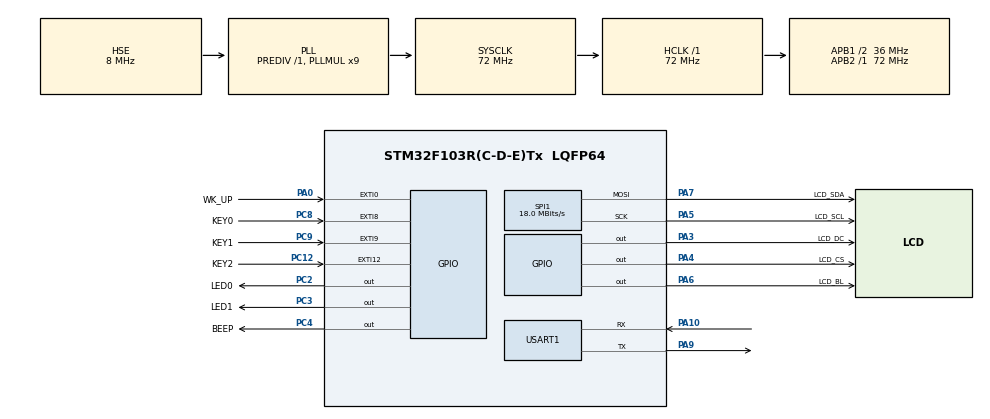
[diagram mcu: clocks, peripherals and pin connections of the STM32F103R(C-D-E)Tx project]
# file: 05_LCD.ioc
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Mcu.Family=STM32F1
Mcu.Name=STM32F103R(C-D-E)Tx
Mcu.Package=LQFP64
NVIC.EXTI0_IRQn=true\:2\:0\:true\:false\:true\:true\:true\:true
NVIC.EXTI15_10_IRQn=true\:2\:2\:true\:false\:true\:true\:true\:true
NVIC.EXTI9_5_IRQn=true\:2\:1\:true\:false\:true\:true\:true\:true
NVIC.PriorityGroup=NVIC_PRIORITYGROUP_2
NVIC.USART1_IRQn=true\:1\:0\:true\:false\:true\:true\:true\:true
PA0-WKUP.GPIO_Label=WK_UP
PA0-WKUP.GPIO_ModeDefaultEXTI=GPIO_MODE_IT_RISING
PA0-WKUP.GPIO_PuPd=GPIO_PULLDOWN
PA0-WKUP.Signal=GPXTI0
PA10.Mode=Asynchronous
PA10.Signal=USART1_RX
PA13.Mode=Serial_Wire
PA13.Signal=SYS_JTMS-SWDIO
PA14.Mode=Serial_Wire
PA14.Signal=SYS_JTCK-SWCLK
PA3.GPIO_Label=LCD_DC
PA3.GPIO_Speed=GPIO_SPEED_FREQ_HIGH
PA3.PinState=GPIO_PIN_SET
PA3.Signal=GPIO_Output
PA4.GPIO_Label=LCD_CS
PA4.GPIO_Speed=GPIO_SPEED_FREQ_HIGH
PA4.PinState=GPIO_PIN_SET
PA4.Signal=GPIO_Output
PA5.GPIO_Label=LCD_SCL
PA5.Mode=TX_Only_Simplex_Unidirect_Master
PA5.Signal=SPI1_SCK
PA6.GPIO_Label=LCD_BL
PA6.PinState=GPIO_PIN_RESET
PA6.Signal=GPIO_Output
PA7.GPIO_Label=LCD_SDA
PA7.Mode=TX_Only_Simplex_Unidirect_Master
PA7.Signal=SPI1_MOSI
PA9.Mode=Asynchronous
PA9.Signal=USART1_TX
PC12.GPIO_Label=KEY2
PC12.GPIO_ModeDefaultEXTI=GPIO_MODE_IT_FALLING
PC12.GPIO_PuPd=GPIO_PULLUP
PC12.Signal=GPXTI12
PC14-OSC32_IN.Mode=LSE-External-Oscillator
PC14-OSC32_IN.Signal=RCC_OSC32_IN
PC15-OSC32_OUT.Mode=LSE-External-Oscillator
PC15-OSC32_OUT.Signal=RCC_OSC32_OUT
PC2.GPIO_Label=LED0
PC2.Signal=GPIO_Output
PC3.GPIO_Label=LED1
PC3.Signal=GPIO_Output
PC4.GPIO_Label=BEEP
PC4.Signal=GPIO_Output
PC8.GPIO_Label=KEY0
PC8.GPIO_ModeDefaultEXTI=GPIO_MODE_IT_FALLING
PC8.GPIO_PuPd=GPIO_PULLUP
PC8.Signal=GPXTI8
PC9.GPIO_Label=KEY1
PC9.GPIO_ModeDefaultEXTI=GPIO_MODE_IT_FALLING
PC9.GPIO_PuPd=GPIO_PULLUP
PC9.Signal=GPXTI9
PD0-OSC_IN.Mode=HSE-External-Oscillator
PD0-OSC_IN.Signal=RCC_OSC_IN
PD1-OSC_OUT.Mode=HSE-External-Oscillator
PD1-OSC_OUT.Signal=RCC_OSC_OUT
ProjectManager.HeapSize=0x200
ProjectManager.StackSize=0x400
ProjectManager.TargetToolchain=STM32CubeIDE
RCC.AHBFreq_Value=72000000
RCC.APB1CLKDivider=RCC_HCLK_DIV2
RCC.APB1Freq_Value=36000000
RCC.APB1TimFreq_Value=72000000
RCC.APB2Freq_Value=72000000
RCC.APB2TimFreq_Value=72000000
RCC.HCLKFreq_Value=72000000
RCC.PLLMUL=RCC_PLL_MUL9
RCC.PLLSourceVirtual=RCC_PLLSOURCE_HSE
RCC.SYSCLKFreq_VALUE=72000000
RCC.SYSCLKSource=RCC_SYSCLKSOURCE_PLLCLK
RCC.USBFreq_Value=72000000
SPI1.BaudRatePrescaler=SPI_BAUDRATEPRESCALER_4
SPI1.CalculateBaudRate=18.0 MBits/s
SPI1.Direction=SPI_DIRECTION_2LINES
SPI1.Mode=SPI_MODE_MASTER
SPI1.VirtualType=VM_MASTER
USART1.VirtualMode=VM_ASYNC
board=custom

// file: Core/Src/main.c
/* USER CODE BEGIN Header */
/**
  ******************************************************************************
  * @file           : main.c
  * @brief          : Main program body
  ******************************************************************************
  * @attention
  *
  * Copyright (c) 2025 STMicroelectronics.
  * All rights reserved.
  *
  * This software is licensed under terms that can be found in the LICENSE file
  * in the root directory of this software component.
  * If no LICENSE file comes with this software, it is provided AS-IS.
  *
  ******************************************************************************
  */
/* USER CODE END Header */
#include "main.h"
#include "spi.h"
#include "usart.h"
#include "gpio.h"

/* USER CODE BEGIN Includes */
#include "lcd_spi_169.h"
#include "lcd_test.h"
#include "app.h"
/* USER CODE END Includes */

void SystemClock_Config(void);

int main(void)
{

  /* MCU Configuration--------------------------------------------------------*/

  /* Reset of all peripherals, Initializes the Flash interface and the Systick. */
  HAL_Init();

  /* Configure the system clock */
  SystemClock_Config();

  /* Initialize all configured peripherals */
  MX_GPIO_Init();
  MX_USART1_UART_Init();
  MX_SPI1_Init();
  /* USER CODE BEGIN 2 */
  hw_init();
  LCD_Init();
  /* USER CODE END 2 */

  /* Infinite loop */
  /* USER CODE BEGIN WHILE */
  while (1)
  {
      LCD_Test_Clear();
      LCD_Test_Text();
    /* USER CODE END WHILE */

  }
}

void SystemClock_Config(void)
{
  RCC_OscInitTypeDef RCC_OscInitStruct = {0};
  RCC_ClkInitTypeDef RCC_ClkInitStruct = {0};

  /** Initializes the RCC Oscillators according to the specified parameters
  * in the RCC_OscInitTypeDef structure.
  */
  RCC_OscInitStruct.OscillatorType = RCC_OSCILLATORTYPE_HSE;
  RCC_OscInitStruct.HSEState = RCC_HSE_ON;
  RCC_OscInitStruct.HSEPredivValue = RCC_HSE_PREDIV_DIV1;
  RCC_OscInitStruct.HSIState = RCC_HSI_ON;
  RCC_OscInitStruct.PLL.PLLState = RCC_PLL_ON;
  RCC_OscInitStruct.PLL.PLLSource = RCC_PLLSOURCE_HSE;
  RCC_OscInitStruct.PLL.PLLMUL = RCC_PLL_MUL9;
  if (HAL_RCC_OscConfig(&RCC_OscInitStruct) != HAL_OK)
  {
    Error_Handler();
  }

  /** Initializes the CPU, AHB and APB buses clocks
  */
  RCC_ClkInitStruct.ClockType = RCC_CLOCKTYPE_HCLK|RCC_CLOCKTYPE_SYSCLK
                              |RCC_CLOCKTYPE_PCLK1|RCC_CLOCKTYPE_PCLK2;
  RCC_ClkInitStruct.SYSCLKSource = RCC_SYSCLKSOURCE_PLLCLK;
  RCC_ClkInitStruct.AHBCLKDivider = RCC_SYSCLK_DIV1;
  RCC_ClkInitStruct.APB1CLKDivider = RCC_HCLK_DIV2;
  RCC_ClkInitStruct.APB2CLKDivider = RCC_HCLK_DIV1;

  if (HAL_RCC_ClockConfig(&RCC_ClkInitStruct, FLASH_LATENCY_2) != HAL_OK)
  {
    Error_Handler();
  }
}

void Error_Handler(void)
{
  __disable_irq();
  while (1)
  {
  }
}
